# CY8C5267AXI_LP051 register map
File version: 0.1
CY8C52LP
Registers are 8-bit, read-write, no defined reset value unless marked. A register's access mark holds for its fields unless they carry their own. Offsets are from the block's base; lines under a group give offsets from that group; [hi:lo] are bit positions; {n}, {i} and the like mark numbered series; 'fields as' and 'values as' point back to an identical list; <NAME> marks a mode.

## Memory map
0x40006466 Status_Reg_1
0x40006470 StartPWMA
0x40006473 EndPWMA
0x40006475 StartPWMB
0x40006574 Freq
0x40006576 Control_Reg_1
0x40006577 EndPWMB

## EndPWMA
Base 0x40006473
0x00 EndPWMA_CONTROL_REG

## StartPWMA
Base 0x40006470
Registers as EndPWMA (with EndPWMA read as StartPWMA).

## StartPWMB
Base 0x40006475
Registers as EndPWMA (with EndPWMA read as StartPWMB).

## Freq
Base 0x40006574
Registers as EndPWMA (with EndPWMA read as Freq).

## Control_Reg_1
Base 0x40006576
Registers as EndPWMA (with EndPWMA read as Control_Reg_1).

## EndPWMB
Base 0x40006577
Registers as EndPWMA (with EndPWMA read as EndPWMB).

## Status_Reg_1
Base 0x40006466
0x00 Status_Reg_1_STATUS_REG
0x20 Status_Reg_1_MASK_REG
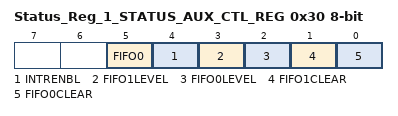
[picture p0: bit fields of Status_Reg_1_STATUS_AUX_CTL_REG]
0x30 Status_Reg_1_STATUS_AUX_CTL_REG
  [5] FIFO0 — FIFO0 clear
    1=ENABLED (Enable counter); 0=DISABLED (Disable counter)
  [4] INTRENBL — Enables or disables the Interrupt
    1=ENABLED (Interrupt enabled); 0=DISABLED (Interrupt disabled)
  [3] FIFO1LEVEL — FIFO level
    1=ENABLED (FIFO LVL: input mode: FIFO at least 1/2 empty; output mode: FIFO at least 1/2 full); 0=DISABLED (FIFO LVL: input mode: FIFO not full; output mode: FIFO not empty)
  [2] FIFO0LEVEL — FIFO level
    values as FIFO1LEVEL
  [1] FIFO1CLEAR — FIFO clear
    1=ENABLED (Clear FIFO state); 0=DISABLED (Normal FIFO operation)
  [0] FIFO0CLEAR — FIFO clear
    values as FIFO1CLEAR
